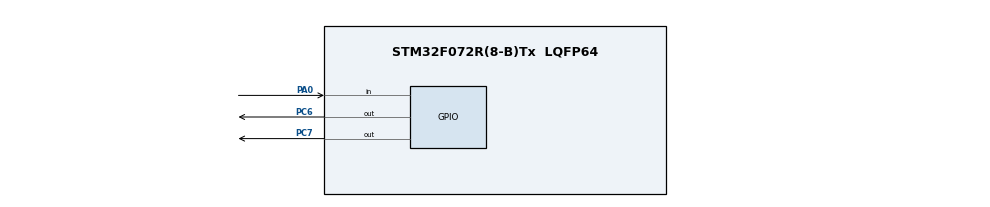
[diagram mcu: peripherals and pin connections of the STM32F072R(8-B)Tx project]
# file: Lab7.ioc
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Mcu.Family=STM32F0
Mcu.Name=STM32F072R(8-B)Tx
Mcu.Package=LQFP64
PA0.Signal=GPIO_Input
PC6.GPIO_Speed=GPIO_SPEED_FREQ_HIGH
PC6.Signal=GPIO_Output
PC7.GPIO_Speed=GPIO_SPEED_FREQ_HIGH
PC7.Signal=GPIO_Output
ProjectManager.HeapSize=0x200
ProjectManager.StackSize=0x400
ProjectManager.TargetToolchain=EWARM V8.32
board=custom

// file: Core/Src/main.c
/* USER CODE BEGIN Header */
/**
  ******************************************************************************
  * @file           : main.c
  * @brief          : Main program body
  ******************************************************************************
  * @attention
  *
  * <h2><center>&copy; Copyright (c) 2021 STMicroelectronics.
  * All rights reserved.</center></h2>
  *
  * This software component is licensed by ST under BSD 3-Clause license,
  * the "License"; You may not use this file except in compliance with the
  * License. You may obtain a copy of the License at:
  *                        opensource.org/licenses/BSD-3-Clause
  *
  ******************************************************************************
  */
/* USER CODE END Header */
#include "main.h"

void SystemClock_Config(void);
static void MX_GPIO_Init(void);

int main(void)
{

  /* MCU Configuration--------------------------------------------------------*/

  /* Reset of all peripherals, Initializes the Flash interface and the Systick. */
  HAL_Init();

  /* Configure the system clock */
  SystemClock_Config();

  /* Initialize all configured peripherals */
  MX_GPIO_Init();
  /* USER CODE BEGIN 2 */
  uint32_t launch_diode = GPIO_PIN_6; /* Przypisanie startowych wartosci dla obu diod */
  uint32_t off_diode = GPIO_PIN_7;

  HAL_GPIO_WritePin(GPIOC, launch_diode, GPIO_PIN_SET); /* zaswiecenie diody */
  /* USER CODE END 2 */

  /* Infinite loop */
  while (1)
  {

    /* USER CODE BEGIN 3 */
    if (HAL_GPIO_ReadPin(GPIOA, GPIO_PIN_0) == GPIO_PIN_SET) /* Sprawdzenie czy przycisk jest wcisniety */
    {
      if (launch_diode == GPIO_PIN_7) /* sprawdzenie ktora dioda jest aktywna */
      {
        launch_diode = GPIO_PIN_6; /* podmiana zmiennych odpowiedzialnych za diode swiecaca */
        off_diode = GPIO_PIN_7; /* i zgaszona */
      } else {
        launch_diode = GPIO_PIN_7; /* analogicznie */
        off_diode = GPIO_PIN_6;
      }
      HAL_GPIO_WritePin(GPIOC, launch_diode, GPIO_PIN_SET); /* zaswiecenie diody */
      HAL_GPIO_WritePin(GPIOC, off_diode, GPIO_PIN_RESET); /* zgaszenie diody */
    }
    HAL_GPIO_TogglePin(GPIOC, launch_diode); /* wlacz/wylacz diode aktywna */
    HAL_Delay(500); /* ustaw opoznienie na 0,5 sekundy */
  }
  /* USER CODE END 3 */
}

void SystemClock_Config(void)
{
  RCC_OscInitTypeDef RCC_OscInitStruct = {0};
  RCC_ClkInitTypeDef RCC_ClkInitStruct = {0};

  /** Initializes the RCC Oscillators according to the specified parameters
  * in the RCC_OscInitTypeDef structure.
  */
  RCC_OscInitStruct.OscillatorType = RCC_OSCILLATORTYPE_HSI;
  RCC_OscInitStruct.HSIState = RCC_HSI_ON;
  RCC_OscInitStruct.HSICalibrationValue = RCC_HSICALIBRATION_DEFAULT;
  RCC_OscInitStruct.PLL.PLLState = RCC_PLL_NONE;
  if (HAL_RCC_OscConfig(&RCC_OscInitStruct) != HAL_OK)
  {
    Error_Handler();
  }
  /** Initializes the CPU, AHB and APB buses clocks
  */
  RCC_ClkInitStruct.ClockType = RCC_CLOCKTYPE_HCLK|RCC_CLOCKTYPE_SYSCLK
                              |RCC_CLOCKTYPE_PCLK1;
  RCC_ClkInitStruct.SYSCLKSource = RCC_SYSCLKSOURCE_HSI;
  RCC_ClkInitStruct.AHBCLKDivider = RCC_SYSCLK_DIV1;
  RCC_ClkInitStruct.APB1CLKDivider = RCC_HCLK_DIV1;

  if (HAL_RCC_ClockConfig(&RCC_ClkInitStruct, FLASH_LATENCY_0) != HAL_OK)
  {
    Error_Handler();
  }
}

static void MX_GPIO_Init(void)
{
  GPIO_InitTypeDef GPIO_InitStruct = {0};

  /* GPIO Ports Clock Enable */
  __HAL_RCC_GPIOA_CLK_ENABLE();
  __HAL_RCC_GPIOC_CLK_ENABLE();

  /*Configure GPIO pin Output Level */
  HAL_GPIO_WritePin(GPIOC, GPIO_PIN_6, GPIO_PIN_SET);

  /*Configure GPIO pin : PA0 */ /* konfiguracja pinu odpowiedizalnego za przycisk */
  GPIO_InitStruct.Pin = GPIO_PIN_0;
  GPIO_InitStruct.Mode = GPIO_MODE_INPUT;
  GPIO_InitStruct.Pull = GPIO_NOPULL;
  HAL_GPIO_Init(GPIOA, &GPIO_InitStruct);

  /*Configure GPIO pins : PC6 PC7 */ /* Konfiguracja pinow odpowiedzialnych za diody */
  GPIO_InitStruct.Pin = GPIO_PIN_6|GPIO_PIN_7;
  GPIO_InitStruct.Mode = GPIO_MODE_OUTPUT_PP;
  GPIO_InitStruct.Pull = GPIO_NOPULL;
  GPIO_InitStruct.Speed = GPIO_SPEED_FREQ_HIGH;
  HAL_GPIO_Init(GPIOC, &GPIO_InitStruct);

}

void Error_Handler(void)
{
  __disable_irq();
  while (1)
  {
  }
}

/************************ (C) COPYRIGHT STMicroelectronics *****END OF FILE****/
